# STM32U5A5 register map
File version: 1.8
CPU: CM33 r0p1, little endian, MPU, FPU, 4 interrupt priority bits
Registers are 32-bit, read-write, reset 0x0 unless marked. A register's access mark holds for its fields unless they carry their own. Offsets are from the block's base; [hi:lo] are bit positions; {n}, {i} and the like mark numbered series.

## PKA — Private key accelerator
Base 0x420C2000
Same registers: SEC_PKA 0x520C2000
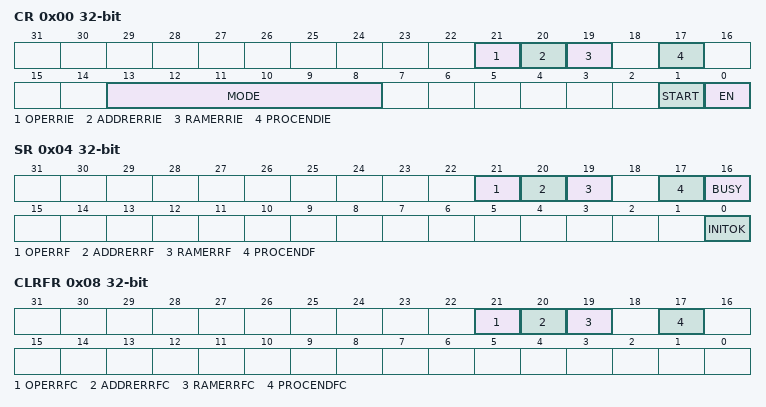
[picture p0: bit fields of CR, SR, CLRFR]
0x00 CR — Control register
  [21] OPERRIE — Operation error interrupt enable
  [20] ADDRERRIE — Address error interrupt
  [19] RAMERRIE — RAM error interrupt enable
  [17] PROCENDIE — End of operation interrupt
  [13:8] MODE — PKA Operation Mode
  [1] START — Start the operation
  [0] EN — Peripheral Enable
0x04 SR ro — PKA status register
  [21] OPERRF
  [20] ADDRERRF
  [19] RAMERRF
  [17] PROCENDF — PKA End of Operation flag
  [16] BUSY — PKA operation is in
  [0] INITOK
0x08 CLRFR wo — PKA clear flag register
  [21] OPERRFC
  [20] ADDRERRFC
  [19] RAMERRFC
  [17] PROCENDFC — Clear PKA End of Operation

## PSSI
Base 0x4202C400
Same registers: SEC_PSSI 0x5202C400
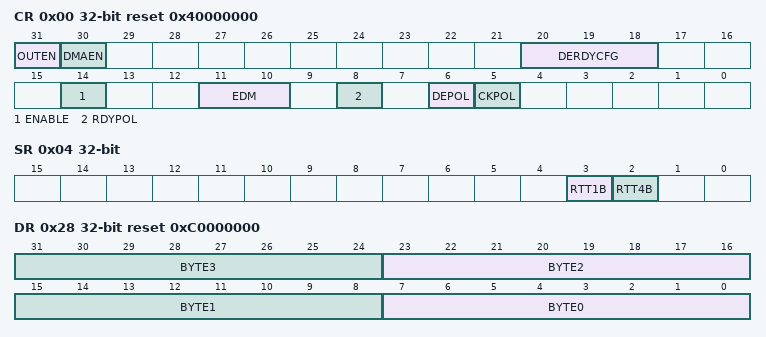
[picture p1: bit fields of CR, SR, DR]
0x00 CR reset 0x40000000 — PSSI control register
  [31] OUTEN — Data direction selection bit
  [30] DMAEN — DMA enable bit
  [20:18] DERDYCFG — Data enable and ready configuration
  [14] ENABLE — PSSI enable
  [11:10] EDM — Extended data mode
  [8] RDYPOL — Ready (PSSI_RDY) polarity
  [6] DEPOL — Data enable (PSSI_DE) polarity
  [5] CKPOL — Parallel data clock polarity
0x04 SR ro — PSSI status register
  [3] RTT1B, [2] RTT4B
0x08 RIS ro — PSSI raw interrupt status register
  [1] OVR_RIS
0x0C IER — PSSI interrupt enable register
  [1] OVR_IE
0x10 MIS ro — PSSI masked interrupt status register
  [1] OVR_MIS
0x14 ICR wo — PSSI interrupt clear register
  [1] OVR_ISC
0x28 DR reset 0xC0000000 — PSSI data register
  [8n+7:8n] BYTE{n} (n=0..3) — Data byte {n}

## RAMCFG
Base 0x40026000
Same registers: SEC_RAMCFG 0x50026000
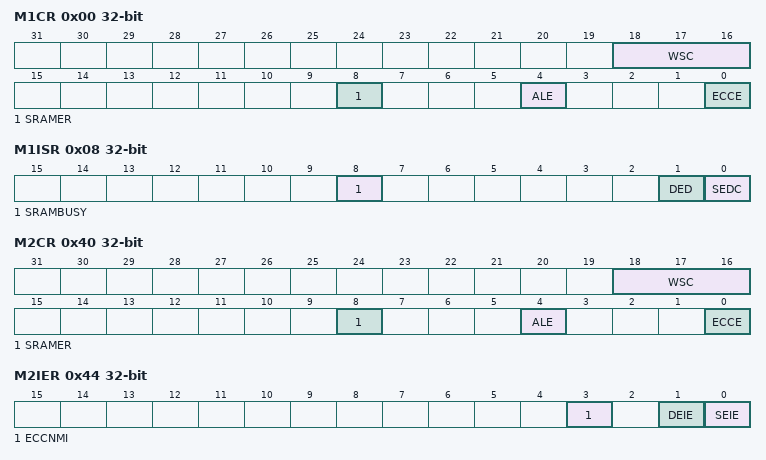
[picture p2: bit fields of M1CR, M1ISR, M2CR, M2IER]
0x00 M1CR — RAMCFG SRAM x control register
  [18:16] WSC, [8] SRAMER, [4] ALE, [0] ECCE
0x08 M1ISR ro — RAMCFG RAMx interrupt status register
  [8] SRAMBUSY, [1] DED, [0] SEDC
0x28 M1ERKEYR wo — RAMCFG SRAM x erase key register
  [7:0] ERASEKEY
0x40 M2CR — RAMCFG SRAM x control register
  [18:16] WSC, [8] SRAMER, [4] ALE, [0] ECCE
0x44 M2IER — RAMCFG SRAM x interrupt enable register
  [3] ECCNMI, [1] DEIE, [0] SEIE
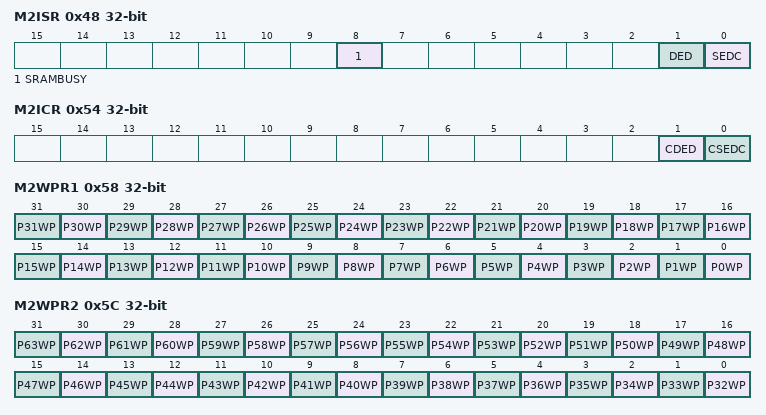
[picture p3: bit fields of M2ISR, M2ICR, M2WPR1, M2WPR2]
0x48 M2ISR ro — RAMCFG RAMx interrupt status register
  [8] SRAMBUSY, [1] DED, [0] SEDC
0x4C M2SEAR ro — RAMCFG RAM x ECC single error address register
  [31:0] ESEA
0x50 M2DEAR ro — RAMCFG RAM x ECC double error address register
  [31:0] EDEA
0x54 M2ICR — RAMCFG RAM x interrupt clear register x
  [1] CDED, [0] CSEDC
0x58 M2WPR1 — RAMCFG SRAM2 write protection register 1
  [n] P{n}WP (n=0..31)
0x5C M2WPR2 — RAMCFG SRAM2 write protection register 2
  [n-32] P{n}WP (n=32..63)
0x64 M2ECCKEYR wo — RAMCFG SRAM x ECC key register
  [7:0] ECCKEY
0x68 M2ERKEYR wo — RAMCFG SRAM x erase key register
  [7:0] ERASEKEY
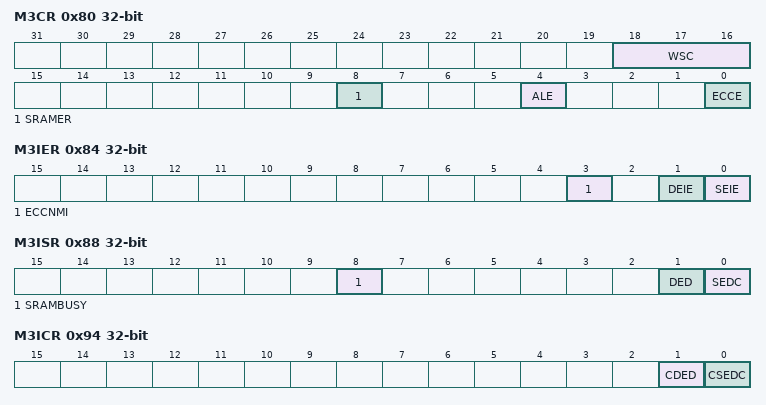
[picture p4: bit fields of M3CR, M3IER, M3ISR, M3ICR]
0x80 M3CR — RAMCFG SRAM x control register
  [18:16] WSC, [8] SRAMER, [4] ALE, [0] ECCE
0x84 M3IER — RAMCFG SRAM x interrupt enable register
  [3] ECCNMI, [1] DEIE, [0] SEIE
0x88 M3ISR ro — RAMCFG RAMx interrupt status register
  [8] SRAMBUSY, [1] DED, [0] SEDC
0x8C M3SEAR ro — RAMCFG RAM x ECC single error address register
  [31:0] ESEA
0x90 M3DEAR ro — RAMCFG RAM x ECC double error address register
  [31:0] EDEA
0x94 M3ICR — RAMCFG RAM x interrupt clear register x
  [1] CDED, [0] CSEDC
0xA4 M3ECCKEYR wo — RAMCFG SRAM x ECC key register
  [7:0] ECCKEY
0xA8 M3ERKEYR wo — RAMCFG SRAM x erase key register
  [7:0] ERASEKEY
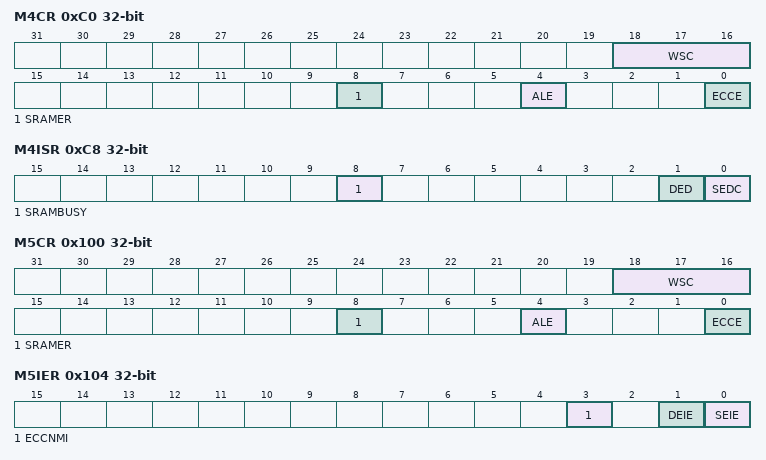
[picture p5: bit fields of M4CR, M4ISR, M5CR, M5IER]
0xC0 M4CR — RAMCFG SRAM x control register
  [18:16] WSC, [8] SRAMER, [4] ALE, [0] ECCE
0xC8 M4ISR ro — RAMCFG RAMx interrupt status register
  [8] SRAMBUSY, [1] DED, [0] SEDC
0xE8 M4ERKEYR wo — RAMCFG SRAM x erase key register
  [7:0] ERASEKEY
0x100 M5CR — RAMCFG SRAM x control register
  [18:16] WSC, [8] SRAMER, [4] ALE, [0] ECCE
0x104 M5IER — RAMCFG SRAM x interrupt enable register
  [3] ECCNMI, [1] DEIE, [0] SEIE
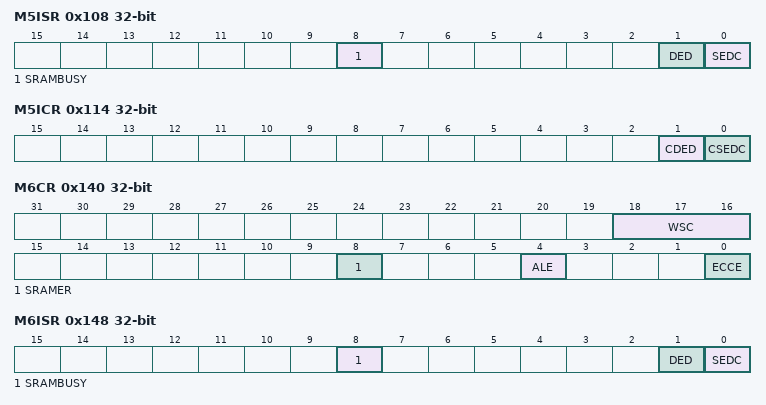
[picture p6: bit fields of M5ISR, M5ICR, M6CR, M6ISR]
0x108 M5ISR ro — RAMCFG RAMx interrupt status register
  [8] SRAMBUSY, [1] DED, [0] SEDC
0x10C M5SEAR ro — RAMCFG RAM x ECC single error address register
  [31:0] ESEA
0x110 M5DEAR ro — RAMCFG RAM x ECC double error address register
  [31:0] EDEA
0x114 M5ICR — RAMCFG RAM x interrupt clear register x
  [1] CDED, [0] CSEDC
0x124 M5ECCKEYR — RAMCFG RAM x interrupt clear register x
  [7:0] ECCKEY
0x128 M5ERKEYR — RAMCFG RAM 5 erase key register
  [7:0] ERASEKEY wo — Erase write protection key
0x140 M6CR — memory x control register
  [18:16] WSC, [8] SRAMER, [4] ALE, [0] ECCE
0x148 M6ISR ro — RAMCFG memory interrupt status register
  [8] SRAMBUSY — SRAM busy with erase operation
    0=No erase operation on going; 1=Erase operation on going
  [1] DED — ECC double error detected
    0=No double error; 1=Double error detected
  [0] SEDC — ECC single error detected and corrected
    0=No single error; 1=Single error detected and corrected
0x168 M6ERKEYR — RAMCFG RAM 6 erase key register
  [7:0] ERASEKEY wo — Erase write protection key
